# RX64M_DOC_Pilot register map
File version: 1.0
RX64M_DOC_Pilot peripheral registers generated from iodefine.h (pilot).
Registers are 16-bit, read-write, reset 0x0 unless marked. A register's access mark holds for its fields unless they carry their own. Offsets are from the block's base; lines under a group give offsets from that group; [hi:lo] are bit positions; {n}, {i} and the like mark numbered series; 'fields as' and 'values as' point back to an identical list; <NAME> marks a mode.

## Memory map
0x0008B080 DOC size 0x6

## DOC
Base 0x0008B080
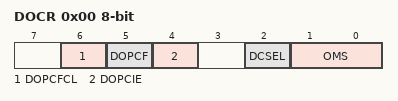
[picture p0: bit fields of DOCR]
0x00 DOCR 8-bit
  [6] DOPCFCL, [5] DOPCF, [4] DOPCIE, [2] DCSEL, [1:0] OMS
0x02 DODIR
0x04 DODSR
